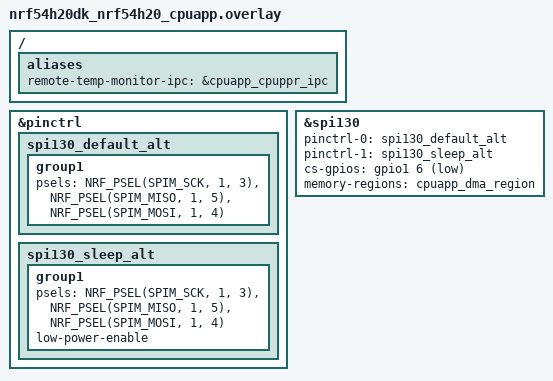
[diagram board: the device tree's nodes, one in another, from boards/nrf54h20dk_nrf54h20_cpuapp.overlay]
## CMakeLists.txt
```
#
# Copyright (c) 2026 Nordic Semiconductor ASA
#
# SPDX-License-Identifier: LicenseRef-Nordic-5-Clause
#

cmake_minimum_required(VERSION 3.20.0)

find_package(Zephyr REQUIRED HINTS $ENV{ZEPHYR_BASE})
project(vpr_offloading)

target_sources(app PRIVATE src/main.c common/ipc_comm.c)

if(CONFIG_SAMPLE_LOCAL_TEMP_MONITOR)
  target_sources(app PRIVATE common/temp_monitor.c)
else()
  target_sources(app PRIVATE src/remote_temp_monitor.c)
endif()

if(CONFIG_SAMPLE_LOCAL_LED_CONTROL)
  target_sources(app PRIVATE common/led_control.c)
else()
  target_sources(app PRIVATE src/remote_led_control.c)
endif()
```

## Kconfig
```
#
# Copyright (c) 2026 Nordic Semiconductor
#
# SPDX-License-Identifier: LicenseRef-Nordic-5-Clause
#

config SAMPLE_LOCAL_TEMP_MONITOR
	bool "Local temperature monitor"

config SAMPLE_LOCAL_LED_CONTROL
	bool "Local LED control"

source "Kconfig.zephyr"
```

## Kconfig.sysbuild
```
#
# Copyright (c) 2026 Nordic Semiconductor ASA
#
# SPDX-License-Identifier: LicenseRef-Nordic-5-Clause
#

choice NETCORE
	default NETCORE_EMPTY

endchoice

if SUPPORT_PPRCORE

choice PPRCORE
	default PPRCORE_REMOTE

config PPRCORE_REMOTE
	bool "remote image"

endchoice

config PPRCORE_IMAGE_NAME
	default "remote" if PPRCORE_REMOTE

config PPRCORE_IMAGE_PATH
	default "$(APP_DIR)/remote" if PPRCORE_REMOTE

endif # SUPPORT_PPRCORE

if SUPPORT_FLPRCORE && !SUPPORT_PPRCORE

choice FLPRCORE
	default FLPRCORE_REMOTE

config FLPRCORE_REMOTE
	bool "remote image"

endchoice

config FLPRCORE_IMAGE_NAME
	default "remote" if FLPRCORE_REMOTE

config FLPRCORE_IMAGE_PATH
	default "$(APP_DIR)/remote" if FLPRCORE_REMOTE

endif # SUPPORT_FLPRCORE && !SUPPORT_PPRCORE

source "share/sysbuild/Kconfig"
```

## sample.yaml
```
sample:
  name: Remote processing on FLPR or PPR
  description: Using co-processor (FLPR or PPR) for background tasks

common:
  sysbuild: true
  harness: console
  harness_config:
    regex:
      - "^.*<inf> app: Average temperature: "
  tags:
    - ci_samples_peripheral_vpr_offloading

tests:
  sample.vpr_offloading.local:
    platform_allow: &offloading_local_platforms
      - nrf54l15dk/nrf54l15/cpuapp
      - nrf54lm20dk/nrf54lm20a/cpuapp
      - nrf54lv10dk/nrf54lv10a/cpuapp
      - nrf54h20dk/nrf54h20/cpuapp
    integration_platforms:
      - nrf54l15dk/nrf54l15/cpuapp
    extra_configs:
      - CONFIG_SAMPLE_LOCAL_TEMP_MONITOR=y
      - CONFIG_SAMPLE_LOCAL_LED_CONTROL=y
      - CONFIG_NRFX_SPIM=y
      - CONFIG_IPC_SERVICE=n
    extra_args:
      - SB_CONFIG_PARTITION_MANAGER=n

  sample.vpr_offloading.flpr:
    extra_args:
      - SB_CONFIG_PARTITION_MANAGER=n
      - SB_CONFIG_RUN_FLPRCORE=y
    platform_allow: &offloading_flpr_platforms
      - nrf54l15dk/nrf54l15/cpuapp
      - nrf54lm20dk/nrf54lm20a/cpuapp
      - nrf54lv10dk/nrf54lv10a/cpuapp
    integration_platforms:
      - nrf54l15dk/nrf54l15/cpuapp

  sample.vpr_offloading.ppr:
    extra_args:
      - SB_CONFIG_RUN_PPRCORE=y
      - vpr_offloading_SNIPPET=nordic-ppr
    platform_allow:
      - nrf54h20dk/nrf54h20/cpuapp
    integration_platforms:
      - nrf54h20dk/nrf54h20/cpuapp

  sample.vpr_offloading.local.current_measurement:
    tags:
      - ppk_power_measure
    platform_allow: *offloading_local_platforms
    integration_platforms:
      - nrf54l15dk/nrf54l15/cpuapp
    extra_configs:
      - CONFIG_SAMPLE_LOCAL_TEMP_MONITOR=y
      - CONFIG_SAMPLE_LOCAL_LED_CONTROL=y
      - CONFIG_NRFX_SPIM=y
      - CONFIG_IPC_SERVICE=n
    extra_args:
      - SB_CONFIG_PARTITION_MANAGER=n
    harness: pytest
    harness_config: &current_meas_harness_cfg
      fixture: ppk_power_measure
      pytest_root:
        - "${CUSTOM_ROOT_TEST_DIR}/test_measure_power_consumption.py::test_measure_current_vpr_offload"

  sample.vpr_offloading.flpr.current_measurement:
    tags:
      - ppk_power_measure
    platform_allow: *offloading_flpr_platforms
    integration_platforms:
      - nrf54l15dk/nrf54l15/cpuapp
    extra_args:
      - SB_CONFIG_PARTITION_MANAGER=n
      - SB_CONFIG_RUN_FLPRCORE=y
    harness: pytest
    harness_config: *current_meas_harness_cfg

  sample.vpr_offloading.ppr.current_measurement:
    tags:
      - ppk_power_measure
    platform_allow:
      - nrf54h20dk/nrf54h20/cpuapp
    integration_platforms:
      - nrf54h20dk/nrf54h20/cpuapp
    extra_args:
      - SB_CONFIG_RUN_PPRCORE=y
      - vpr_offloading_SNIPPET=nordic-ppr
    harness: pytest
    harness_config: *current_meas_harness_cfg
```

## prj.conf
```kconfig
# Copyright (c) 2026 Nordic Semiconductor ASA
# SPDX-License-Identifier: LicenseRef-Nordic-5-Clause
CONFIG_IPC_SERVICE=y
CONFIG_MBOX=y

# Enable logging and use asynchronous UART API which is more efficient
CONFIG_LOG=y
CONFIG_LOG_BUFFER_SIZE=8192
CONFIG_UART_ASYNC_API=y
CONFIG_LOG_BACKEND_UART_ASYNC=y
CONFIG_PINCTRL_KEEP_SLEEP_STATE=y

CONFIG_CPU_LOAD=y

CONFIG_TEST_RANDOM_GENERATOR=y
CONFIG_TIMER_RANDOM_GENERATOR=y
```

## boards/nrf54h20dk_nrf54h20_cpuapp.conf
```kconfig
CONFIG_PM=y
CONFIG_PM_DEVICE=y
CONFIG_PM_DEVICE_RUNTIME=y
CONFIG_SOC_NRF54H20_CPURAD_ENABLE=y
```

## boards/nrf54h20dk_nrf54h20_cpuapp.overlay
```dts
/*
 * Copyright (c) 2026 Nordic Semiconductor ASA
 *
 * SPDX-License-Identifier: LicenseRef-Nordic-5-Clause
 */

/ {
	aliases {
		remote-temp-monitor-ipc = &cpuapp_cpuppr_ipc;
	};
};

&pinctrl {
	spi130_default_alt: spi130_default_alt {
		group1 {
			psels = <NRF_PSEL(SPIM_SCK, 1, 3)>,
				<NRF_PSEL(SPIM_MISO, 1, 5)>,
				<NRF_PSEL(SPIM_MOSI, 1, 4)>;
		};
	};

	spi130_sleep_alt: spi130_sleep_alt {
		group1 {
			psels = <NRF_PSEL(SPIM_SCK, 1, 3)>,
				<NRF_PSEL(SPIM_MISO, 1, 5)>,
				<NRF_PSEL(SPIM_MOSI, 1, 4)>;
			low-power-enable;
		};
	};
};

app_spi: &spi130 {
	status = "okay";
	pinctrl-0 = <&spi130_default_alt>;
	pinctrl-1 = <&spi130_sleep_alt>;
	pinctrl-names = "default", "sleep";
	cs-gpios = <&gpio1 6 GPIO_ACTIVE_LOW>;
	memory-regions = <&cpuapp_dma_region>;
};
```

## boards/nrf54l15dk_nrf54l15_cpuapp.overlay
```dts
/*
 * Copyright (c) 2026 Nordic Semiconductor ASA
 *
 * SPDX-License-Identifier: LicenseRef-Nordic-5-Clause
 */

/ {
	aliases {
		remote-temp-monitor-ipc = &ipc0;
	};
};

&pinctrl {
	spi22_default_alt: spi22_default_alt {
		group1 {
			psels = <NRF_PSEL(SPIM_SCK, 1, 8)>,
				<NRF_PSEL(SPIM_MISO, 1, 10)>,
				<NRF_PSEL(SPIM_MOSI, 1, 9)>;
		};
	};

	spi22_sleep_alt: spi22_sleep_alt {
		group1 {
			psels = <NRF_PSEL(SPIM_SCK, 1, 8)>,
				<NRF_PSEL(SPIM_MISO, 1, 10)>,
				<NRF_PSEL(SPIM_MOSI, 1, 9)>;
			low-power-enable;
		};
	};
};

app_spi: &spi22 {
	status = "okay";
	pinctrl-0 = <&spi22_default_alt>;
	pinctrl-1 = <&spi22_sleep_alt>;
	pinctrl-names = "default", "sleep";
	overrun-character = <0x00>;
	cs-gpios = <&gpio1 11 GPIO_ACTIVE_LOW>;
};
```

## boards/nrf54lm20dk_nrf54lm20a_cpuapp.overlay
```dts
/*
 * Copyright (c) 2026 Nordic Semiconductor ASA
 *
 * SPDX-License-Identifier: LicenseRef-Nordic-5-Clause
 */

/ {
	aliases {
		remote-temp-monitor-ipc = &ipc0;
	};
};

&pinctrl {
	spi22_default_alt: spi22_default_alt {
		group1 {
			psels = <NRF_PSEL(SPIM_SCK, 1, 23)>,
				<NRF_PSEL(SPIM_MISO, 1, 30)>,
				<NRF_PSEL(SPIM_MOSI, 1, 13)>;
		};
	};

	spi22_sleep_alt: spi22_sleep_alt {
		group1 {
			psels = <NRF_PSEL(SPIM_SCK, 1, 23)>,
				<NRF_PSEL(SPIM_MISO, 1, 30)>,
				<NRF_PSEL(SPIM_MOSI, 1, 13)>;
			low-power-enable;
		};
	};
};

app_spi: &spi22 {
	status = "okay";
	pinctrl-0 = <&spi22_default_alt>;
	pinctrl-1 = <&spi22_sleep_alt>;
	pinctrl-names = "default", "sleep";
	cs-gpios = <&gpio1 9 GPIO_ACTIVE_LOW>;
};
```

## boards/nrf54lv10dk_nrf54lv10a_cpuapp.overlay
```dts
/*
 * Copyright (c) 2026 Nordic Semiconductor ASA
 *
 * SPDX-License-Identifier: LicenseRef-Nordic-5-Clause
 */

/* The nordic-flpr snippet splits the 192k RAM into 123k for the application core,
 * 4k for the default IPC buffers (2k per direction), 64k for the FLPR code and data,
 * and 1k for the FLPR hibernation space.
 */

/ {
	aliases {
		remote-temp-monitor-ipc = &ipc0;
	};
};

&pinctrl {
	spi21_default_alt: spi21_default_alt {
		group1 {
			psels = <NRF_PSEL(SPIM_SCK, 1, 19)>,
				<NRF_PSEL(SPIM_MISO, 1, 20)>,
				<NRF_PSEL(SPIM_MOSI, 1, 21)>;
		};
	};

	spi21_sleep_alt: spi21_sleep_alt {
		group1 {
			psels = <NRF_PSEL(SPIM_SCK, 1, 19)>,
				<NRF_PSEL(SPIM_MISO, 1, 20)>,
				<NRF_PSEL(SPIM_MOSI, 1, 21)>;
			low-power-enable;
		};
	};
};

app_spi: &spi21 {
	status = "okay";
	pinctrl-0 = <&spi21_default_alt>;
	pinctrl-1 = <&spi21_sleep_alt>;
	pinctrl-names = "default", "sleep";
	overrun-character = <0x00>;
	cs-gpios = <&gpio1 22 GPIO_ACTIVE_LOW>;
};
```

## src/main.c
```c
/*
 * Copyright (c) 2026 Nordic Semiconductor ASA
 *
 * SPDX-License-Identifier: LicenseRef-Nordic-5-Clause
 */

#include "../common/temp_monitor.h"
#include "../common/led_control.h"
#include <zephyr/kernel.h>
#include <zephyr/logging/log.h>

#ifdef CONFIG_CPU_LOAD
#include <zephyr/sys/cpu_load.h>
#elif defined(CONFIG_NRF_CPU_LOAD)
#include <debug/cpu_load.h>
#endif

LOG_MODULE_REGISTER(app);

/** @brief Temperature control event handler.
 *
 * Handler reports periodically about average temperature. There are additional
 * events triggered when temperature exceeds the limits.
 */
static void temp_event_handler(uint8_t type, int16_t value)
{
	int decimal = value / 100;
	uint32_t frac = ((value < 0) ? -value : value) % 100;

	switch (type) {
	case TEMP_MONITOR_MSG_AVG:
		LOG_INF("Average temperature: %d.%d", decimal, frac);
		break;
	case TEMP_MONITOR_MSG_ABOVE:
		LOG_INF("Temperature above the limit: %d.%d", decimal, frac);
		break;
	case TEMP_MONITOR_MSG_BELOW:
		LOG_INF("Temperature below the limit: %d.%d", decimal, frac);
		break;
	default:
		break;
	}
}

int main(void)
{
	/* Sample the sensor at 1000 Hz, report average every 1000 measurements. Report if
	 * temperature is outside of 20'C-28'C range.
	 */
	struct temp_monitor_start temp_monitor_params = {
		.limith = 2800, .limitl = 2000, .report_avg_period = 1000, .odr = 1000};
	static const uint32_t period_on[] = {100, 500, 800};
	static const uint32_t period_off[] = {900, 500, 200};
	uint32_t cfg_idx = 0;
	int rv;

#ifdef CONFIG_CPU_LOAD
	(void)cpu_load_get(true);
#elif defined(CONFIG_NRF_CPU_LOAD)
	cpu_load_reset();
#endif

	if (IS_ENABLED(CONFIG_SAMPLE_LOCAL_TEMP_MONITOR)) {
		printk("Sample runs modules on the application core\n");
	} else {
		printk("Sample runs modules on the VPR core\n");
	}

	temp_monitor_set_handler(temp_event_handler);
	/*return 0;*/

	while (1) {
		rv = temp_monitor_start(&temp_monitor_params);
		if (rv < 0) {
			LOG_ERR("Temperature monitor start failed, err:%d", rv);
		}

		rv = led_control_start(period_on[cfg_idx], period_off[cfg_idx]);
		if (rv < 0) {
			LOG_ERR("Led control failed, err:%d", rv);
		}
		cfg_idx = (cfg_idx == ARRAY_SIZE(period_on) - 1) ? 0 : cfg_idx + 1;

		k_msleep(2500);

		rv = temp_monitor_stop();
		if (rv < 0) {
			LOG_ERR("Temperature monitor stop failed, err:%d", rv);
		}

		rv = led_control_stop();
		if (rv < 0) {
			LOG_ERR("Led control stop failed, err:%d", rv);
		}

#ifdef CONFIG_CPU_LOAD
		int load = cpu_load_get(true);

		printk("CPU load: %d.%d\n", load / 10, load % 10);
#elif defined(CONFIG_NRF_CPU_LOAD)
		int load = cpu_load_get();

		printk("CPU load: %d.%d\n", load / 1000, load % 1000);
#endif

		k_msleep(500);
	}

	return 0;
}
```

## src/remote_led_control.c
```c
/*
 * Copyright (c) 2026 Nordic Semiconductor ASA
 *
 * SPDX-License-Identifier: LicenseRef-Nordic-5-Clause
 */
#include "../common/ipc_comm.h"
#include "../common/led_control.h"
#include <zephyr/logging/log.h>
LOG_MODULE_REGISTER(led_ctrl);

/* Module implements LED control API using remote service on the VPR core. */

static struct ipc_comm_data ipc_helper_data;
static struct ipc_comm ipc_helper;
static struct ipc_comm ipc_helper = IPC_COMM_INIT(LED_CONTROL_EP_NAME, NULL, NULL,
						  DEVICE_DT_GET(DT_ALIAS(remote_temp_monitor_ipc)),
						  &ipc_helper_data, &ipc_helper);

static int rem_led_control_init(void)
{
	return ipc_comm_init(&ipc_helper);
}

int led_control_start(uint32_t period_on, uint32_t period_off)
{
	struct led_control_msg msg = {.type = LED_CONTROL_MSG_START,
				      .start = {
					      .period_on = period_on,
					      .period_off = period_off,
				      }};

	return ipc_comm_send(&ipc_helper, &msg, sizeof(msg));
}

int led_control_stop(void)
{
	struct led_control_msg msg = {.type = LED_CONTROL_MSG_STOP};

	return ipc_comm_send(&ipc_helper, &msg, sizeof(msg));
}

#if CONFIG_NORDIC_VPR_LAUNCHER_INIT_PRIORITY > CONFIG_IPC_SERVICE_REG_BACKEND_PRIORITY
#define BASE_PRIO CONFIG_NORDIC_VPR_LAUNCHER_INIT_PRIORITY
#else
#define BASE_PRIO CONFIG_IPC_SERVICE_REG_BACKEND_PRIORITY
#endif

/* Need to be started after vpr launcher and launcher can be postponed if STM logging is used. */
SYS_INIT(rem_led_control_init, POST_KERNEL, UTIL_INC(BASE_PRIO));
```

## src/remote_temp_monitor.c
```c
/*
 * Copyright (c) 2026 Nordic Semiconductor ASA
 *
 * SPDX-License-Identifier: LicenseRef-Nordic-5-Clause
 */
#include <zephyr/logging/log.h>
LOG_MODULE_REGISTER(temp_monitor);
#include "../common/ipc_comm.h"
#include "../common/temp_monitor.h"

/* Module implements temperature monitor API as a communication with VPR core
 * which executes the operations.
 */
static void ipc_comm_cb(void *user_data, const void *buf, size_t len);
static temp_monitor_event_handler_t event_handler;
static struct ipc_comm_data ipc_helper_data;
static struct ipc_comm ipc_helper;
static struct ipc_comm ipc_helper = IPC_COMM_INIT(TEMP_MONITOR_EP_NAME, ipc_comm_cb, NULL,
						  DEVICE_DT_GET(DT_ALIAS(remote_temp_monitor_ipc)),
						  &ipc_helper_data, &ipc_helper);

/* IPC callback */
static void ipc_comm_cb(void *user_data, const void *buf, size_t len)
{
	const struct temp_monitor_msg *msg = buf;

	if (event_handler) {
		event_handler(msg->type, msg->report.value);
	}
}

static int rem_temp_init(void)
{
	return ipc_comm_init(&ipc_helper);
}

void temp_monitor_set_handler(temp_monitor_event_handler_t handler)
{
	event_handler = handler;
}

int temp_monitor_start(const struct temp_monitor_start *params)
{
	struct temp_monitor_msg msg = {.type = TEMP_MONITOR_MSG_START, .start = *params};

	return ipc_comm_send(&ipc_helper, &msg, sizeof(msg));
}

int temp_monitor_stop(void)
{
	struct temp_monitor_msg msg = {.type = TEMP_MONITOR_MSG_STOP};

	return ipc_comm_send(&ipc_helper, &msg, sizeof(msg));
}

#if CONFIG_NORDIC_VPR_LAUNCHER_INIT_PRIORITY > CONFIG_IPC_SERVICE_REG_BACKEND_PRIORITY
#define BASE_PRIO CONFIG_NORDIC_VPR_LAUNCHER_INIT_PRIORITY
#else
#define BASE_PRIO CONFIG_IPC_SERVICE_REG_BACKEND_PRIORITY
#endif

/* Need to be started after vpr launcher and launcher can be postponed if STM logging is used. */
SYS_INIT(rem_temp_init, POST_KERNEL, UTIL_INC(BASE_PRIO));
```
